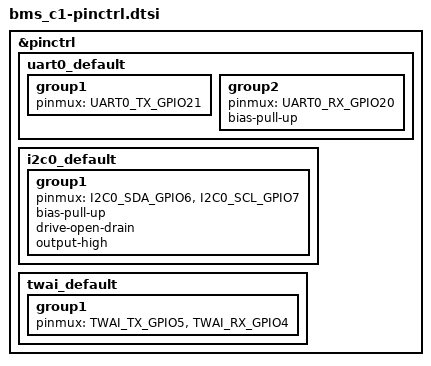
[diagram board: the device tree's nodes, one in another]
/*
 * Copyright (c) The Libre Solar Project Contributors
 *
 * SPDX-License-Identifier: Apache-2.0
 */

#include <dt-bindings/pinctrl/esp32c3-pinctrl.h>
#include <zephyr/dt-bindings/pinctrl/esp-pinctrl-common.h>
#include <zephyr/dt-bindings/pinctrl/esp32c3-gpio-sigmap.h>

&pinctrl {
	uart0_default: uart0_default {
		group1 {
			pinmux = <UART0_TX_GPIO21>;
		};
		group2 {
			pinmux = <UART0_RX_GPIO20>;
			bias-pull-up;
		};
	};

	i2c0_default: i2c0_default {
		group1 {
			pinmux = <I2C0_SDA_GPIO6>,
				 <I2C0_SCL_GPIO7>;
			bias-pull-up;
			drive-open-drain;
			output-high;
		};
	};

	twai_default: twai_default {
		group1 {
			pinmux = <TWAI_TX_GPIO5>,
				 <TWAI_RX_GPIO4>;
		};
	};
};
